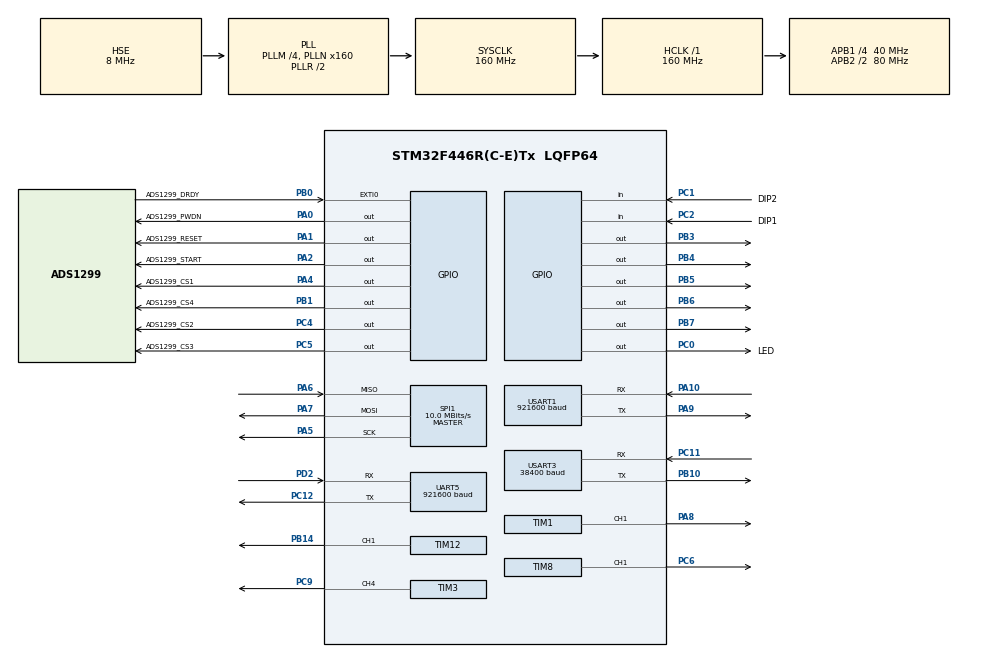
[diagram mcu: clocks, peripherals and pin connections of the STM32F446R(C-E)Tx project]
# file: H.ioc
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Dma.Request0=USART1_TX
Dma.Request1=USART3_TX
Dma.USART1_TX.0.Direction=DMA_MEMORY_TO_PERIPH
Dma.USART1_TX.0.FIFOMode=DMA_FIFOMODE_DISABLE
Dma.USART1_TX.0.Instance=DMA2_Stream7
Dma.USART1_TX.0.MemDataAlignment=DMA_MDATAALIGN_BYTE
Dma.USART1_TX.0.MemInc=DMA_MINC_ENABLE
Dma.USART1_TX.0.Mode=DMA_NORMAL
Dma.USART1_TX.0.PeriphDataAlignment=DMA_PDATAALIGN_BYTE
Dma.USART1_TX.0.PeriphInc=DMA_PINC_DISABLE
Dma.USART1_TX.0.Priority=DMA_PRIORITY_LOW
Dma.USART3_TX.1.Direction=DMA_MEMORY_TO_PERIPH
Dma.USART3_TX.1.FIFOMode=DMA_FIFOMODE_DISABLE
Dma.USART3_TX.1.Instance=DMA1_Stream3
Dma.USART3_TX.1.MemDataAlignment=DMA_MDATAALIGN_BYTE
Dma.USART3_TX.1.MemInc=DMA_MINC_ENABLE
Dma.USART3_TX.1.Mode=DMA_NORMAL
Dma.USART3_TX.1.PeriphDataAlignment=DMA_PDATAALIGN_BYTE
Dma.USART3_TX.1.PeriphInc=DMA_PINC_DISABLE
Dma.USART3_TX.1.Priority=DMA_PRIORITY_HIGH
Mcu.Family=STM32F4
Mcu.Name=STM32F446R(C-E)Tx
Mcu.Package=LQFP64
NVIC.DMA1_Stream3_IRQn=true\:0\:0\:false\:false\:true\:false\:true\:true
NVIC.DMA2_Stream7_IRQn=true\:0\:0\:false\:false\:true\:false\:true\:true
NVIC.EXTI0_IRQn=true\:5\:0\:true\:false\:true\:true\:true\:true
NVIC.PriorityGroup=NVIC_PRIORITYGROUP_4
NVIC.SPI1_IRQn=true\:0\:0\:false\:false\:true\:true\:true\:true
NVIC.UART5_IRQn=true\:0\:0\:true\:false\:true\:true\:true\:true
NVIC.USART1_IRQn=true\:3\:0\:true\:false\:true\:true\:true\:true
NVIC.USART3_IRQn=true\:0\:0\:false\:false\:true\:true\:true\:true
PA0-WKUP.GPIO_Label=ADS1299_PWDN
PA0-WKUP.GPIO_Speed=GPIO_SPEED_FREQ_VERY_HIGH
PA0-WKUP.Signal=GPIO_Output
PA1.GPIO_Label=ADS1299_RESET
PA1.GPIO_Speed=GPIO_SPEED_FREQ_VERY_HIGH
PA1.Signal=GPIO_Output
PA10.Mode=Asynchronous
PA10.Signal=USART1_RX
PA13.Mode=Serial_Wire
PA13.Signal=SYS_JTMS-SWDIO
PA14.Mode=Serial_Wire
PA14.Signal=SYS_JTCK-SWCLK
PA2.GPIO_Label=ADS1299_START
PA2.GPIO_Speed=GPIO_SPEED_FREQ_VERY_HIGH
PA2.Signal=GPIO_Output
PA4.GPIO_Label=ADS1299_CS1
PA4.GPIO_Speed=GPIO_SPEED_FREQ_VERY_HIGH
PA4.Signal=GPIO_Output
PA5.Mode=Full_Duplex_Master
PA5.Signal=SPI1_SCK
PA6.Mode=Full_Duplex_Master
PA6.Signal=SPI1_MISO
PA7.Mode=Full_Duplex_Master
PA7.Signal=SPI1_MOSI
PA8.Signal=S_TIM1_CH1
PA9.Mode=Asynchronous
PA9.Signal=USART1_TX
PB0.GPIO_Label=ADS1299_DRDY
PB0.GPIO_ModeDefaultEXTI=GPIO_MODE_IT_FALLING
PB0.GPIO_PuPd=GPIO_PULLUP
PB0.Signal=GPXTI0
PB1.GPIO_Label=ADS1299_CS4
PB1.Signal=GPIO_Output
PB10.Mode=Asynchronous
PB10.Signal=USART3_TX
PB14.Signal=S_TIM12_CH1
PB3.Signal=GPIO_Output
PB4.Signal=GPIO_Output
PB5.Signal=GPIO_Output
PB6.Signal=GPIO_Output
PB7.Signal=GPIO_Output
PC0.GPIO_Label=LED
PC0.GPIO_Speed=GPIO_SPEED_FREQ_VERY_HIGH
PC0.PinState=GPIO_PIN_SET
PC0.Signal=GPIO_Output
PC1.GPIO_Label=DIP2
PC1.Signal=GPIO_Input
PC11.Mode=Asynchronous
PC11.Signal=USART3_RX
PC12.Mode=Asynchronous
PC12.Signal=UART5_TX
PC2.GPIO_Label=DIP1
PC2.Signal=GPIO_Input
PC4.GPIO_Label=ADS1299_CS2
PC4.Signal=GPIO_Output
PC5.GPIO_Label=ADS1299_CS3
PC5.Signal=GPIO_Output
PC6.Signal=S_TIM8_CH1
PC9.Signal=S_TIM3_CH4
PD2.Mode=Asynchronous
PD2.Signal=UART5_RX
PH0-OSC_IN.Mode=HSE-External-Oscillator
PH0-OSC_IN.Signal=RCC_OSC_IN
PH1-OSC_OUT.Mode=HSE-External-Oscillator
PH1-OSC_OUT.Signal=RCC_OSC_OUT
ProjectManager.HeapSize=0x9000
ProjectManager.StackSize=0x9000
ProjectManager.TargetToolchain=MDK-ARM V5.32
RCC.AHBFreq_Value=160000000
RCC.APB1CLKDivider=RCC_HCLK_DIV4
RCC.APB1Freq_Value=40000000
RCC.APB1TimFreq_Value=80000000
RCC.APB2CLKDivider=RCC_HCLK_DIV2
RCC.APB2Freq_Value=80000000
RCC.APB2TimFreq_Value=160000000
RCC.CortexFreq_Value=160000000
RCC.HCLKFreq_Value=160000000
RCC.HSE_VALUE=8000000
RCC.PLLM=4
RCC.PLLN=160
RCC.PLLSourceVirtual=RCC_PLLSOURCE_HSE
RCC.SYSCLKFreq_VALUE=160000000
RCC.SYSCLKSource=RCC_SYSCLKSOURCE_PLLRCLK
RCC.USBFreq_Value=160000000
RCC.VCOOutputFreq_Value=320000000
SH.S_TIM12_CH1.0=TIM12_CH1,PWM Generation1 CH1
SH.S_TIM1_CH1.0=TIM1_CH1,PWM Generation1 CH1
SH.S_TIM3_CH4.0=TIM3_CH4,PWM Generation4 CH4
SH.S_TIM8_CH1.0=TIM8_CH1,PWM Generation1 CH1
SPI1.BaudRatePrescaler=SPI_BAUDRATEPRESCALER_8
SPI1.CLKPhase=SPI_PHASE_2EDGE
SPI1.CalculateBaudRate=10.0 MBits/s
SPI1.Direction=SPI_DIRECTION_2LINES
SPI1.Mode=SPI_MODE_MASTER
SPI1.VirtualType=VM_MASTER
STMicroelectronics.X-CUBE-ALGOBUILD.1.3.0.LibraryCcDSPOoLibraryJjDSPOoLibrary=true
TIM1.Channel-PWM\ Generation1\ CH1=TIM_CHANNEL_1
TIM1.Period=1429
TIM1.Prescaler=16000 - 1
TIM1.Pulse-PWM\ Generation1\ CH1=715
TIM12.Channel-PWM\ Generation1\ CH1=TIM_CHANNEL_1
TIM12.Period=614
TIM12.Prescaler=9999
TIM12.Pulse-PWM\ Generation1\ CH1=307
TIM2.Period=65535
TIM2.Prescaler=160-1
TIM3.Channel-PWM\ Generation4\ CH4=TIM_CHANNEL_4
TIM3.Period=888
TIM3.Prescaler=9999
TIM3.Pulse-PWM\ Generation4\ CH4=444
TIM8.Channel-PWM\ Generation1\ CH1=TIM_CHANNEL_1
TIM8.Period=999
TIM8.Prescaler=14545
TIM8.Pulse-PWM\ Generation1\ CH1=500
UART5.BaudRate=921600
UART5.VirtualMode=Asynchronous
USART1.BaudRate=921600
USART1.VirtualMode=VM_ASYNC
USART3.BaudRate=38400
USART3.VirtualMode=VM_ASYNC
VP_STMicroelectronics.X-CUBE-ALGOBUILD_VS_DSPOoLibraryJjLibrary_1.3.0_1.3.0.Mode=DSPOoLibraryJjLibrary
VP_TIM2_VS_ClockSourceINT.Mode=Internal
board=custom

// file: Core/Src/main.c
/* USER CODE BEGIN Header */
/**
  ******************************************************************************
  * @file           : main.c
  * @brief          : Main program body
  ******************************************************************************
  * @attention
  *
  * Copyright (c) 2024 STMicroelectronics.
  * All rights reserved.
  *
  * This software is licensed under terms that can be found in the LICENSE file
  * in the root directory of this software component.
  * If no LICENSE file comes with this software, it is provided AS-IS.
  *
  ******************************************************************************
  */
/**
 ****************************************************************************************************
 * @file        MAIN.C
 * @author      XJIE
 * @version     V1.00
 * @date        2025-04-04
 * @brief       TODO
 *
 ****************************************************************************************************
 * @attention		NULL
 *
 * CSDN:				https://blog.csdn.net/NANY_ying.com
 * Github:			https://github.com/xiaojie25
 *
 *
 *
 ****************************************************************************************************
 */
/* USER CODE END Header */
#include "main.h"
#include "dma.h"
#include "spi.h"
#include "tim.h"
#include "usart.h"
#include "gpio.h"

/* USER CODE BEGIN Includes */
#include "task.h"
#include "task_scheduler.h"
#include "uart_ext.h"
#include "ADS1299.h"
#include "delay.h"
/* USER CODE END Includes */

void SystemClock_Config(void);

int main(void)
{
  /* USER CODE BEGIN 1 */
	TaskSchedulerInit();
  /* USER CODE END 1 */

  /* MCU Configuration--------------------------------------------------------*/

  /* Reset of all peripherals, Initializes the Flash interface and the Systick. */
  HAL_Init();

  /* Configure the system clock */
  SystemClock_Config();

  /* Initialize all configured peripherals */
  MX_GPIO_Init();
  MX_DMA_Init();
  MX_SPI1_Init();
  MX_USART1_UART_Init();
  MX_UART5_Init();
  MX_TIM1_Init();
  MX_TIM3_Init();
  MX_TIM12_Init();
  MX_TIM2_Init();
  MX_USART3_UART_Init();
  MX_TIM8_Init();
  /* USER CODE BEGIN 2 */
	TaskInit();
  /* USER CODE END 2 */

  /* Infinite loop */
  while (1)
  {

    /* USER CODE BEGIN 3 */
		TaskSchedulerMainLoop();
  }
  /* USER CODE END 3 */
}

void SystemClock_Config(void)
{
  RCC_OscInitTypeDef RCC_OscInitStruct = {0};
  RCC_ClkInitTypeDef RCC_ClkInitStruct = {0};

  /** Configure the main internal regulator output voltage
  */
  __HAL_RCC_PWR_CLK_ENABLE();
  __HAL_PWR_VOLTAGESCALING_CONFIG(PWR_REGULATOR_VOLTAGE_SCALE1);

  /** Initializes the RCC Oscillators according to the specified parameters
  * in the RCC_OscInitTypeDef structure.
  */
  RCC_OscInitStruct.OscillatorType = RCC_OSCILLATORTYPE_HSE;
  RCC_OscInitStruct.HSEState = RCC_HSE_ON;
  RCC_OscInitStruct.PLL.PLLState = RCC_PLL_ON;
  RCC_OscInitStruct.PLL.PLLSource = RCC_PLLSOURCE_HSE;
  RCC_OscInitStruct.PLL.PLLM = 4;
  RCC_OscInitStruct.PLL.PLLN = 160;
  RCC_OscInitStruct.PLL.PLLP = RCC_PLLP_DIV2;
  RCC_OscInitStruct.PLL.PLLQ = 2;
  RCC_OscInitStruct.PLL.PLLR = 2;
  if (HAL_RCC_OscConfig(&RCC_OscInitStruct) != HAL_OK)
  {
    Error_Handler();
  }

  /** Initializes the CPU, AHB and APB buses clocks
  */
  RCC_ClkInitStruct.ClockType = RCC_CLOCKTYPE_HCLK|RCC_CLOCKTYPE_SYSCLK
                              |RCC_CLOCKTYPE_PCLK1|RCC_CLOCKTYPE_PCLK2;
  RCC_ClkInitStruct.SYSCLKSource = RCC_SYSCLKSOURCE_PLLRCLK;
  RCC_ClkInitStruct.AHBCLKDivider = RCC_SYSCLK_DIV1;
  RCC_ClkInitStruct.APB1CLKDivider = RCC_HCLK_DIV4;
  RCC_ClkInitStruct.APB2CLKDivider = RCC_HCLK_DIV2;

  if (HAL_RCC_ClockConfig(&RCC_ClkInitStruct, FLASH_LATENCY_5) != HAL_OK)
  {
    Error_Handler();
  }
}

void Error_Handler(void)
{
  __disable_irq();
  while (1)
  {
  }
}
